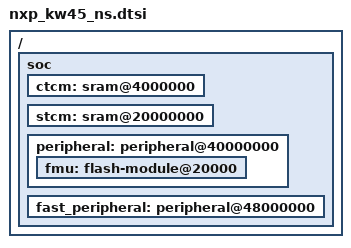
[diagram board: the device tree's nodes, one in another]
/*
 * Copyright 2023 NXP
 *
 * SPDX-License-Identifier: Apache-2.0
 */

#include <mem.h>
#include <arm/armv8-m.dtsi>

/ {
	soc {
		ctcm: sram@4000000 {
			ranges = <0x0 0x4000000 DT_SIZE_K(16)>;
		};

		stcm: sram@20000000 {
			ranges = <0x0 0x20000000 DT_SIZE_K(112)>;
		};

		peripheral: peripheral@40000000 {
			ranges = <0x0 0x40000000 DT_SIZE_K(512)>;

			fmu: flash-module@20000 {
				ranges = <0x0 0x0 DT_SIZE_M(1)>;
			};
		};

		fast_peripheral: peripheral@48000000 {
			ranges = <0x0 0x48000000 DT_SIZE_M(8)>;
		};
	};
};

#include "nxp_kw45_common.dtsi"
